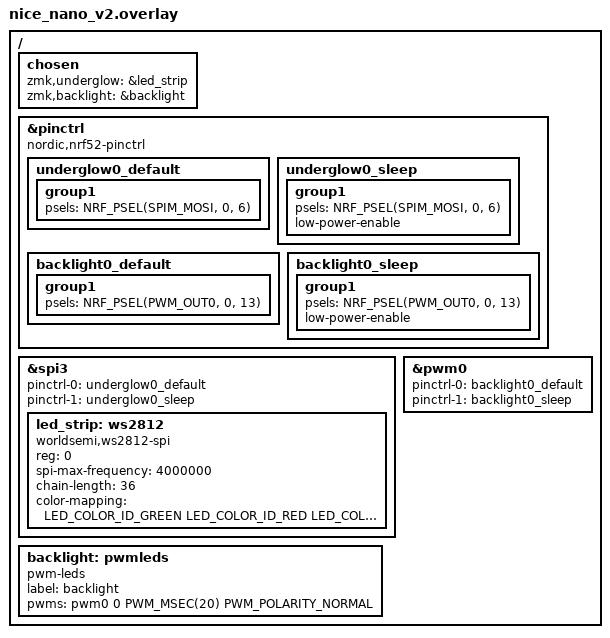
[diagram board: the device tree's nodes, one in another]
/ {
    // This is the root node of the Devicetree.  It's always present.

    chosen {
        // The 'chosen' node is used to select which hardware features ZMK should use.

        zmk,underglow = &led_strip;  // Connect ZMK underglow to the 'led_strip' node.
        zmk,backlight = &backlight;  // Connect ZMK backlight to the 'backlight' node.
        // IMPORTANT:  Make sure these lines have a semicolon (;) at the end.
    };

    &pinctrl {
        //  This node configures the microcontroller's pin control.  It's where you
        //  tell ZMK which pins are used for what.
        compatible = "nordic,nrf52-pinctrl";  //  This line should be present for nRF52 MCUs.

        underglow0_default: underglow0_default {
            group1 {
                psels = <NRF_PSEL(SPIM_MOSI, 0, 6)>;  // Example:  SPI MOSI on P0.06.  **ADJUST THIS PIN!**
                //  The NRF_PSEL macro is specific to Nordic MCUs.  The arguments are:
                //  -  Peripheral (SPIM_MOSI, PWM_OUT0, etc.)
                //  -  Port (0 for P0, 1 for P1, etc.)
                //  -  Pin number within the port.
            };
        };

        underglow0_sleep: underglow0_sleep {
            group1 {
                psels = <NRF_PSEL(SPIM_MOSI, 0, 6)>;  // Example:  **ADJUST THIS PIN!** Should match default.
                low-power-enable;  //  Important for power saving.
            };
        };

        backlight0_default: backlight0_default {
            group1 {
                psels = <NRF_PSEL(PWM_OUT0, 0, 13)>;  // Example: PWM on P0.13.  **ADJUST THIS PIN!**
            };
        };

        backlight0_sleep: backlight0_sleep {
            group1 {
                psels = <NRF_PSEL(PWM_OUT0, 0, 13)>;  // Example: **ADJUST THIS PIN!** Should match default
                low-power-enable;
            };
        };
    };

    &spi3 {  //  Configure the SPI peripheral (if used for underglow).  Check your board's .dts file.
        status = "okay";  //  Enable the SPI peripheral.
        pinctrl-0 = <&underglow0_default>;  //  Use the pin configuration from above.
        pinctrl-1 = <&underglow0_sleep>;    //  Use the sleep pin config.
        pinctrl-names = "default", "sleep";  //  Give names to the pin configurations.

        led_strip: ws2812 {
            //  Define the LED strip.  'ws2812' is an example; change if needed.
            compatible = "worldsemi,ws2812-spi";  //  Driver for WS2812 LEDs.  **ADJUST IF DIFFERENT LEDS**
            reg = <0>;  //  Register address (usually 0 for SPI).
            spi-max-frequency = <4000000>;  //  Max SPI frequency.  WS2812 is often 4MHz.
            chain-length = <36>;  //  **IMPORTANT:  Number of LEDs on *ONE HALF* of the Sofle!**
            color-mapping = <LED_COLOR_ID_GREEN LED_COLOR_ID_RED LED_COLOR_ID_BLUE>;  //  GRB order for WS2812
        };
    };

    &pwm0 {  //  Configure the PWM peripheral (if used for backlight).
        status = "okay";
        pinctrl-0 = <&backlight0_default>;
        pinctrl-1 = <&backlight0_sleep>;
        pinctrl-names = "default", "sleep";
    };

    backlight: pwmleds {
        compatible = "pwm-leds";
        label = "backlight";
        pwms = <&pwm0 0 PWM_MSEC(20) PWM_POLARITY_NORMAL>;  //  **ADJUST PWM PARAMS IF NEEDED**
    };
};
